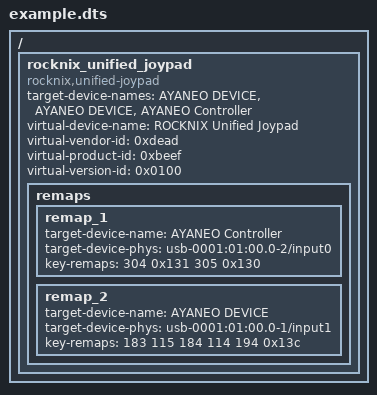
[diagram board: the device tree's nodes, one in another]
/ {
	/*
	 * This node configures the unified_joypad driver. It should be added
	 * to your target device's main .dts file.
	 */
	rocknix_unified_joypad {
		/*
		 * This 'compatible' string is mandatory. It's the key that the Linux
		 * kernel uses to find and load the correct driver for this node.
		 * It must not be changed.
		 */
		compatible = "rocknix,unified-joypad";

		/*
		 * A list of all physical device names the driver should manage.
		 * A "slot" is reserved for each entry. If you have two physical
		 * devices with the same name, you MUST list the name twice.
		 */
		target-device-names = "AYANEO DEVICE",      // Slot for the first device
				      "AYANEO DEVICE",      // Slot for the second device
				      "AYANEO Controller";

		/*
		 * --- Optional: Virtual Device Properties ---
		 * These properties override the appearance of the final virtual device.
		 * This is useful for ensuring compatibility with applications that
		 * expect a standard controller.
		 */
		virtual-device-name = "ROCKNIX Unified Joypad";
		virtual-vendor-id = <0xdead>;      // USB Vendor ID in hexadecimal
		virtual-product-id = <0xbeef>;     // USB Product ID in hexadecimal
		virtual-version-id = <0x0100>;     // Device version in hexadecimal

		/*
		 * --- Optional: Button Remapping Rules ---
		 * This sub-node contains specific remapping configurations.
		 */
		remaps {
			/*
			 * Remap rule for the "AYANEO Controller".
			 * Since its name is unique, using 'target-device-phys' is optional
			 * but recommended for a more robust configuration.
			 */
			remap_1 {
				target-device-name = "AYANEO Controller";
				target-device-phys = "usb-0001:01:00.0-2/input0";
				key-remaps = <
					/* from        to */
					304         0x131   // BTN_SOUTH -> BTN_EAST
					305         0x130   // BTN_EAST  -> BTN_SOUTH
				>;
			};

			/*
			 * Remap rule for a specific "AYANEO DEVICE". We use the unique
			 * 'target-device-phys' property to distinguish it from the other
			 * device that shares the same name.
			 */
			remap_2 {
				target-device-name = "AYANEO DEVICE";
				target-device-phys = "usb-0001:01:00.0-1/input1";
				key-remaps = <
					/* from        to (decimal) */
					183         115           // KEY_F13 -> KEY_VOLUMEUP
					184         114           // KEY_F14 -> KEY_VOLUMEDOWN
					194         0x13c         // KEY_F24 -> BTN_MODE
				>;
			};
		};
	};
};
